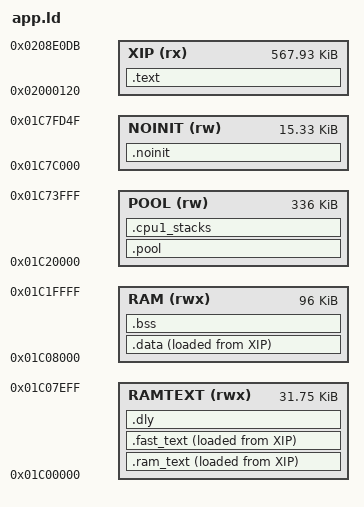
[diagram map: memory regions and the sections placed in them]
/* SPDX-License-Identifier: GPL-3.0-only
 * Copyright (C) 2026 Leo Kuroshita (@kurogedelic), Hügelton Instruments */
/* Felucca memory map.
 * Code + constants execute in place from XIP (app.bin offset 0 = 0x02000120).
 * 0x01C00000..0x01C07F00 holds .ram_text (code that must run while the flash
 * is busy: the flash driver), .fast_text (the audio's hot code) and .dly; the
 * last 256 bytes (0x01C07F00..) are crt0's STATUS (BIGORNA build 32: the limit
 * Melodee documents).
 * RAM  : .data/.bss (96 KiB)
 * POOL : big zero-initialised buffers (FX lines, canvases), section .pool
 * STACKS with 256-byte guard bands; NOINIT survives resets and UBOOT entry.
 * 0x01C7FD50.. is reserved: boot_info, boot-state mailbox, vector table. */
MEMORY
{
    XIP    (rx)  : ORIGIN = 0x02000120, LENGTH = 0x8DFBC
    RAMTEXT (rwx): ORIGIN = 0x01C00000, LENGTH = 0x7F00
    RAM    (rwx) : ORIGIN = 0x01C08000, LENGTH = 96K
    POOL   (rw)  : ORIGIN = 0x01C20000, LENGTH = 0x54000
    NOINIT (rw)  : ORIGIN = 0x01C7C000, LENGTH = 0x3D50
}
SECTIONS
{
    .text : { KEEP(*(.text.crt0)) *(.text*) *(.rodata*) . = ALIGN(4); _etext = .; } > XIP
    .ram_text : { _rt_start = .; KEEP(*(.ram_text*)) . = ALIGN(4); _rt_end = .; } > RAMTEXT AT > XIP
    _rt_load = LOADADDR(.ram_text);
    /* the audio's hottest code (FAST), run from RAM: never waits for the flash's cache. It may call into XIP */
    .fast_text : { . = ALIGN(4); _ft_start = .; KEEP(*(.fast_text*)) . = ALIGN(4); _ft_end = .; } > RAMTEXT AT > XIP
    _ft_load = LOADADDR(.fast_text);
    /* data in what the RAM for code leaves free (DLYMEM: part of the delay's line), zeroed by its owner */
    .dly (NOLOAD) : { . = ALIGN(4); *(.dly_mem*) . = ALIGN(4); } > RAMTEXT
    .data : { . = ALIGN(4); _data_start = .; *(.data*) *(.sdata*) . = ALIGN(4); _data_end = .; } > RAM AT > XIP
    _data_load = LOADADDR(.data);
    .bss (NOLOAD) : { _bss_start = .; *(.bss*) *(.sbss*) *(COMMON) . = ALIGN(4); _bss_end = .; } > RAM
    .pool (NOLOAD) : { _pool_start = .; *(.pool*) . = ALIGN(4); _pool_end = .; } > POOL
    /* CPU1's stacks (hal/fm1_multicore.h: user 4 KiB, then supervisor 4 KiB; BIGORNA build 32) */
    .cpu1_stacks (NOLOAD) : { . = ALIGN(32); _cpu1_stacks_lo = .; KEEP(*(.cpu1_stacks)) _cpu1_stacks_hi = .; } > POOL
    _cpu1_ustack_top = _cpu1_stacks_lo + 4096;
    _cpu1_sstack_top = _cpu1_stacks_lo + 8192;
    .noinit (NOLOAD) : { *(.noinit*) } > NOINIT
    _guard0 = 0x01C74000; _ustack_lo = 0x01C74100; _ustack_top = 0x01C7A000;
    _guard1 = 0x01C7A000; _sstack_lo = 0x01C7A100; _sstack_top = 0x01C7C000;
    /DISCARD/ : { *(.comment) *(.note*) }
}
